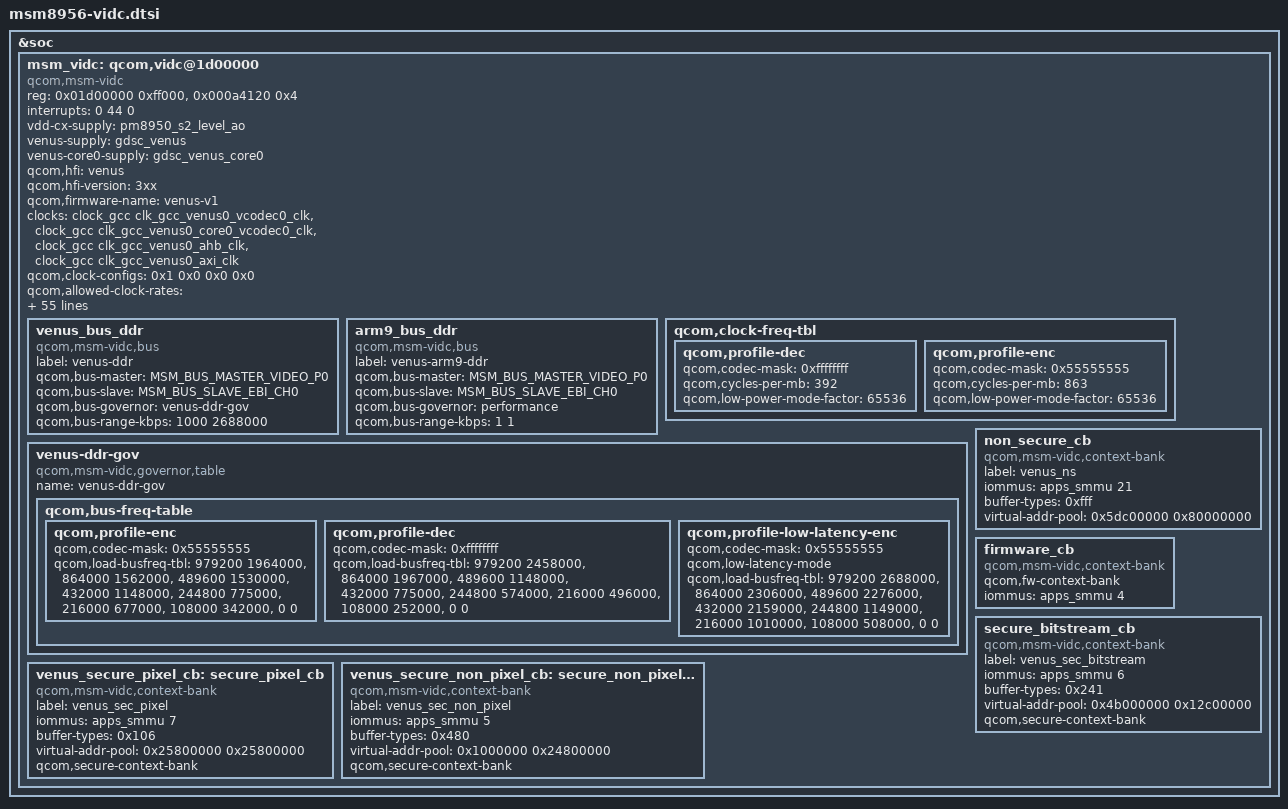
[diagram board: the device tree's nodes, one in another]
/* Copyright (c) 2014-2015, 2017, The Linux Foundation. All rights reserved.
 * (c) 2017, AngeloGioacchino Del Regno <kholk11@gmail.com>
 *
 * This program is free software; you can redistribute it and/or modify
 * it under the terms of the GNU General Public License version 2 and
 * only version 2 as published by the Free Software Foundation.
 *
 * This program is distributed in the hope that it will be useful,
 * but WITHOUT ANY WARRANTY; without even the implied warranty of
 * MERCHANTABILITY or FITNESS FOR A PARTICULAR PURPOSE.  See the
 * GNU General Public License for more details.
 */

#include <dt-bindings/interrupt-controller/arm-gic.h>

&soc {
	msm_vidc: qcom,vidc@1d00000 {
		compatible = "qcom,msm-vidc";
		reg = <0x01d00000 0xff000>,
			<0x000a4120 0x4>;
		reg-names = "vidc", "efuse";
		interrupts = <0 44 0>;

		vdd-cx-supply = <&pm8950_s2_level_ao>;
		venus-supply = <&gdsc_venus>;
		venus-core0-supply = <&gdsc_venus_core0>;

		qcom,hfi = "venus";
		qcom,hfi-version = "3xx";
		qcom,firmware-name = "venus-v1";
		//qcom,platform-version = <0x600000000 0x1D>;

		clocks =
			<&clock_gcc clk_gcc_venus0_vcodec0_clk>,
			<&clock_gcc clk_gcc_venus0_core0_vcodec0_clk>,
			<&clock_gcc clk_gcc_venus0_ahb_clk>,
			<&clock_gcc clk_gcc_venus0_axi_clk>;

		clock-names = "core_clk", "core0_clk", "iface_clk", "bus_clk";
		qcom,clock-configs = <0x1 0x0 0x0 0x0>;
		qcom,allowed-clock-rates = <466000000 400000000 360000000
					    228570000 133333333 100000000
					    80000000 72727200>;
		qcom,slave-side-cp;
		qcom,sw-power-collapse;
		qcom,reset-clock-control;
		qcom,regulator-scaling;
		qcom,max-hw-load = <1011840>; /* 3840 x 2176 @ 30 fps + 3840 x 2176 @ 1 fps */
		qcom,dcvs-min-load = <734400>; /* 1920 x 1088 @ 90fps */
		qcom,dcvs-min-mbperframe = <32400>; /* 3840 x 2160 */
		//qcom,max-hw-load = <979200>; /* TURBO, UHD30E */

		qcom,load-freq-tbl =
			<979200 466000000 0x55555555>, /* TURBO, UHD30E   */
			<979200 400000000 0xffffffff>, /* NOM+ , UHD30D   */
			<734400 360000000 0xffffffff>, /* NOM  , 1080p90D */
			<734400 400000000 0x55555555>, /* NOM+ , 1080p90E */
			<489600 228570000 0xffffffff>, /* SVS  , 1080p60D */
			<489600 466000000 0x55555555>, /* TURBO, 1080p60E */
			<432000 228570000 0xffffffff>, /* SVS  , 720p120D */
			<432000 400000000 0x55555555>, /* NOM+ , 720p120E */
			<244800 133333333 0xffffffff>, /* SVS- , 1080p30D */
			<244800 228570000 0x55555555>, /* SVS  , 1080p30E */
			<216000 100000000 0xffffffff>, /* SVS- , 720p60D  */
			<216000 228570000 0x55555555>, /* SVS  , 720p60E  */
			<108000 80000000 0xffffffff>,  /* SVS--, 720p30D  */
			<108000 100000000 0x55555555>, /* SVS- , 720p30E  */
			<36000 72727200 0xffffffff>,   /* SVS--, 480p30D  */
			<36000 80000000 0x55555555>;   /* SVS--, 480p30E  */

		qcom,dcvs-tbl =
			/* Dec UHD@30 H.264, HEVC, VP8, VP9 - NOM to NOM+*/
			<816000 816000 979200 0x3f00000c>,

			/* Enc UHD@30 H.264/HEVC Turbo to Nom+ */
			<897600 821100 979200 0x4000004>,

			/* Enc True4K@24 H.264/HEVC Nom to Nom+ */
			<816000 720000 835584 0x4000004>;

		qcom,dcvs-limit =
			<32400 24>, /* Encoder UHD */
			<32400 24>; /* Decoder UHD */

		qcom,qdss-presets =
			<0x6025000 0x1000>,
			<0x6026000 0x1000>,
			<0x6021000 0x1000>,
			<0x6002000 0x1000>,
			<0x9180000 0x1000>,
			<0x9181000 0x1000>;

		qcom,reg-presets =
			<0xE0020 0x05555556>,
			<0xE0024 0x05555556>,
			<0x80124 0x00000003>;

		qcom,clock-voltage-tbl =
			<72727200 RPM_SMD_REGULATOR_LEVEL_SVS>,
			<80000000 RPM_SMD_REGULATOR_LEVEL_SVS>,
			<100000000 RPM_SMD_REGULATOR_LEVEL_SVS>,
			<133333333 RPM_SMD_REGULATOR_LEVEL_SVS>,
			<228570000 RPM_SMD_REGULATOR_LEVEL_SVS>,
			<310667000 RPM_SMD_REGULATOR_LEVEL_SVS_PLUS>,
			<360000000 RPM_SMD_REGULATOR_LEVEL_NOM>,
			<400000000 RPM_SMD_REGULATOR_LEVEL_NOM_PLUS>,
			<466000000 RPM_SMD_REGULATOR_LEVEL_TURBO>;

		qcom,vp9d-clock-voltage-tbl =
			<72727200 RPM_SMD_REGULATOR_LEVEL_SVS>,
			<80000000 RPM_SMD_REGULATOR_LEVEL_SVS>,
			<100000000 RPM_SMD_REGULATOR_LEVEL_SVS>,
			<133333333 RPM_SMD_REGULATOR_LEVEL_SVS>,
			<228570000 RPM_SMD_REGULATOR_LEVEL_SVS_PLUS>,
			<310667000 RPM_SMD_REGULATOR_LEVEL_NOM>,
			<360000000 RPM_SMD_REGULATOR_LEVEL_NOM_PLUS>,
			<400000000 RPM_SMD_REGULATOR_LEVEL_TURBO>;

		/* VIDC buses */
		venus_bus_ddr {
			compatible = "qcom,msm-vidc,bus";
			label = "venus-ddr";
			qcom,bus-master = <MSM_BUS_MASTER_VIDEO_P0>;
			qcom,bus-slave = <MSM_BUS_SLAVE_EBI_CH0>;
			qcom,bus-governor = "venus-ddr-gov";
			qcom,bus-range-kbps = <1000 2688000>;
		};

		arm9_bus_ddr {
			compatible = "qcom,msm-vidc,bus";
			label = "venus-arm9-ddr";
			qcom,bus-master = <MSM_BUS_MASTER_VIDEO_P0>;
			qcom,bus-slave = <MSM_BUS_SLAVE_EBI_CH0>;
			qcom,bus-governor = "performance";
			qcom,bus-range-kbps = <1 1>;
		};

		qcom,clock-freq-tbl {
			qcom,profile-dec {
				qcom,codec-mask = <0xffffffff>;
				qcom,cycles-per-mb = <392>;
				qcom,low-power-mode-factor = <65536>;
			};
			qcom,profile-enc {
				qcom,codec-mask = <0x55555555>;
				qcom,cycles-per-mb = <863>;
				qcom,low-power-mode-factor = <65536>;
			};
		};

		/* Bus governor tables */
		venus-ddr-gov {
		    compatible = "qcom,msm-vidc,governor,table";
		    name = "venus-ddr-gov";
		    status = "ok";
		    qcom,bus-freq-table {
			qcom,profile-enc {
				/* Codec mask for "all encoders" */
				qcom,codec-mask = <0x55555555>;
				qcom,load-busfreq-tbl =
					<979200 1964000>,  /* UHD30E     */
					<864000 1562000>,  /* 720p240LPE */
					<489600 1530000>,  /* 1080p60E   */
					<432000 1148000>,  /* 720p120E   */
					<244800 775000>,   /* 1080p30E   */
					<216000 677000>,   /* 720p60E    */
					<108000 342000>,   /* 720p30E    */
					<0 0>;
			};

			qcom,profile-dec {
				/* Codec mask for "all decoders" */
				qcom,codec-mask = <0xffffffff>;
				qcom,load-busfreq-tbl =
					<979200 2458000>,  /* UHD30D     */
					<864000 1967000>,  /* 720p240D   */
					<489600 1148000>,  /* 1080p60D   */
					<432000 775000>,   /* 720p120D   */
					<244800 574000>,   /* 1080p30D   */
					<216000 496000>,   /* 720p60E    */
					<108000 252000>,   /* 720p30D    */
					<0 0>;
			};

			qcom,profile-low-latency-enc {
				/* Codec mask for "all encoders" */
				qcom,codec-mask = <0x55555555>;
				qcom,low-latency-mode;
				qcom,load-busfreq-tbl =
					<979200 2688000>,  /* UHD30E     */
					<864000 2306000>,  /* 720p240LPE */
					<489600 2276000>,  /* 1080p60E   */
					<432000 2159000>,  /* 720p120E   */
					<244800 1149000>,  /* 1080p30E   */
					<216000 1010000>,  /* 720p60E    */
					<108000 508000>,   /* 720p30E    */
					<0 0>;
			};
		    };
		};


		/* IOMMU Contexts: Non Secure */
		/* venus_ns
		 * Address pool from 1500MB to 3532MB && 3532MB to 3548MB
		 *
		 *			 Pool 1
		 *    Start: 0x5dc00000		Length: 0x7f000000
		 *    Allowed Types: 0x7ff	SMEM Partition: 0
		 *
		 *			 Pool 2
		 *    Start: 0xdcc00000		Length: 0x1000000
		 *    Allowed Types: 0x800	SMEM Partition: 1
		 */

		non_secure_cb {
			compatible = "qcom,msm-vidc,context-bank";
			label = "venus_ns";
			iommus = <&apps_smmu 21>;
			/* Buffer types relative to the two address pools */
			buffer-types = <0xfff>;
			virtual-addr-pool = <0x5dc00000 0x80000000>;
		};

		/* IOMMU Contexts: Secure */
		firmware_cb {
			compatible = "qcom,msm-vidc,context-bank";
			/* Firmware context bank is unlabeled in 4.4 */
			/* note: old-style label is "venus_fw" */
			qcom,fw-context-bank;
			iommus = <&apps_smmu 4>;
		};

		/* Address pool from 1200MB to 1500MB */
		secure_bitstream_cb {
			compatible = "qcom,msm-vidc,context-bank";
			label = "venus_sec_bitstream";
			iommus = <&apps_smmu 6>;
			buffer-types = <0x241>;
			virtual-addr-pool = <0x4b000000 0x12c00000>;
			qcom,secure-context-bank;
		};

		/* Address pool from 616MB to 1200MB */
		venus_secure_pixel_cb: secure_pixel_cb {
			compatible = "qcom,msm-vidc,context-bank";
			label = "venus_sec_pixel";
			iommus = <&apps_smmu 7>;
			buffer-types = <0x106>;
			virtual-addr-pool = <0x25800000 0x25800000>;
			qcom,secure-context-bank;
		};

		/* Address pool from 16MB to 616MB */
		venus_secure_non_pixel_cb: secure_non_pixel_cb {
			compatible = "qcom,msm-vidc,context-bank";
			label = "venus_sec_non_pixel";
			iommus = <&apps_smmu 5>;
			buffer-types = <0x480>;
			virtual-addr-pool = <0x1000000 0x24800000>;
			qcom,secure-context-bank;
		};
	};
};
